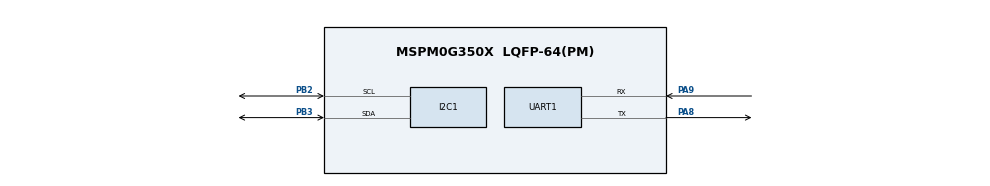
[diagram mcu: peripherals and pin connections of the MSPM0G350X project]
/**
 * @cliArgs --device "MSPM0G350X" --part "Default" --package "LQFP-64(PM)" --product "mspm0_sdk@2.09.00.02"
 * @versions {"tool":"1.25.0+4268"}
 */

/**
 * Import the modules used in this configuration.
 */
const I2C           = scripting.addModule("/ti/driverlib/I2C", {}, false);
const I2C1          = I2C.addInstance();
const PWM           = scripting.addModule("/ti/driverlib/PWM", {}, false);
const PWM1          = PWM.addInstance();
const PWM2          = PWM.addInstance();
const QEI           = scripting.addModule("/ti/driverlib/QEI", {}, false);
const QEI1          = QEI.addInstance();
const SYSCTL        = scripting.addModule("/ti/driverlib/SYSCTL");
const TIMER         = scripting.addModule("/ti/driverlib/TIMER", {}, false);
const TIMER1        = TIMER.addInstance();
const UART          = scripting.addModule("/ti/driverlib/UART", {}, false);
const UART1         = UART.addInstance();
const ProjectConfig = scripting.addModule("/ti/project_config/ProjectConfig");

/**
 * Write custom configuration values to the imported modules.
 */
const gate7  = system.clockTree["MFCLKGATE"];
gate7.enable = true;

I2C1.$name                             = "COMM_I2C";
I2C1.peripheral.sdaPin.$assign         = "PB3";
I2C1.peripheral.sclPin.$assign         = "PB2";
I2C1.sdaPinConfig.$name                = "ti_driverlib_gpio_GPIOPinGeneric0";
I2C1.sdaPinConfig.hideOutputInversion  = scripting.forceWrite(false);
I2C1.sdaPinConfig.onlyInternalResistor = scripting.forceWrite(false);
I2C1.sdaPinConfig.passedPeripheralType = scripting.forceWrite("Digital");
I2C1.sclPinConfig.$name                = "ti_driverlib_gpio_GPIOPinGeneric1";
I2C1.sclPinConfig.hideOutputInversion  = scripting.forceWrite(false);
I2C1.sclPinConfig.onlyInternalResistor = scripting.forceWrite(false);
I2C1.sclPinConfig.passedPeripheralType = scripting.forceWrite("Digital");

const Board = scripting.addModule("/ti/driverlib/Board", {}, false);

PWM1.$name                              = "LEFT_MOTOR";
PWM1.clockDivider                       = 8;
PWM1.clockPrescale                      = 20;
PWM1.timerCount                         = 2000;
PWM1.timerStartTimer                    = true;
PWM1.ccIndex                            = [0];
PWM1.PWM_CHANNEL_0.$name                = "ti_driverlib_pwm_PWMTimerCC0";
PWM1.ccp0PinConfig.direction            = scripting.forceWrite("OUTPUT");
PWM1.ccp0PinConfig.hideOutputInversion  = scripting.forceWrite(false);
PWM1.ccp0PinConfig.onlyInternalResistor = scripting.forceWrite(false);
PWM1.ccp0PinConfig.passedPeripheralType = scripting.forceWrite("Digital");
PWM1.ccp0PinConfig.$name                = "ti_driverlib_gpio_GPIOPinGeneric4";

PWM2.$name                              = "RIGHT_MOTOR";
PWM2.ccIndex                            = [0];
PWM2.clockDivider                       = 8;
PWM2.clockPrescale                      = 20;
PWM2.timerCount                         = 2000;
PWM2.timerStartTimer                    = true;
PWM2.PWM_CHANNEL_0.$name                = "ti_driverlib_pwm_PWMTimerCC2";
PWM2.ccp0PinConfig.direction            = scripting.forceWrite("OUTPUT");
PWM2.ccp0PinConfig.hideOutputInversion  = scripting.forceWrite(false);
PWM2.ccp0PinConfig.onlyInternalResistor = scripting.forceWrite(false);
PWM2.ccp0PinConfig.passedPeripheralType = scripting.forceWrite("Digital");
PWM2.ccp0PinConfig.$name                = "ti_driverlib_gpio_GPIOPinGeneric6";

QEI1.$name               = "QEI_0";
QEI1.clockDivider        = 2;
QEI1.timerStartTimer     = true;
QEI1.ccp0PinConfig.$name = "ti_driverlib_gpio_GPIOPinGeneric5";
QEI1.ccp1PinConfig.$name = "ti_driverlib_gpio_GPIOPinGeneric7";

SYSCTL.clockTreeEn = true;

TIMER1.$name           = "TIMER_0";
TIMER1.timerPeriod     = "5 ms";
TIMER1.timerClkDiv     = 4;
TIMER1.timerStartTimer = true;
TIMER1.interrupts      = ["ZERO"];

UART1.$name                            = "UART_DE";
UART1.uartClkSrc                       = "MFCLK";
UART1.enabledInterrupts                = ["RX"];
UART1.peripheral.rxPin.$assign         = "PA9";
UART1.peripheral.txPin.$assign         = "PA8";
UART1.txPinConfig.direction            = scripting.forceWrite("OUTPUT");
UART1.txPinConfig.hideOutputInversion  = scripting.forceWrite(false);
UART1.txPinConfig.onlyInternalResistor = scripting.forceWrite(false);
UART1.txPinConfig.passedPeripheralType = scripting.forceWrite("Digital");
UART1.txPinConfig.$name                = "ti_driverlib_gpio_GPIOPinGeneric2";
UART1.rxPinConfig.hideOutputInversion  = scripting.forceWrite(false);
UART1.rxPinConfig.onlyInternalResistor = scripting.forceWrite(false);
UART1.rxPinConfig.passedPeripheralType = scripting.forceWrite("Digital");
UART1.rxPinConfig.$name                = "ti_driverlib_gpio_GPIOPinGeneric3";

ProjectConfig.genLibCMSIS = true;

/**
 * Pinmux solution for unlocked pins/peripherals. This ensures that minor changes to the automatic solver in a future
 * version of the tool will not impact the pinmux you originally saw.  These lines can be completely deleted in order to
 * re-solve from scratch.
 */
I2C1.peripheral.$suggestSolution           = "I2C1";
Board.peripheral.$suggestSolution          = "DEBUGSS";
Board.peripheral.swclkPin.$suggestSolution = "PA20";
Board.peripheral.swdioPin.$suggestSolution = "PA19";
PWM1.peripheral.$suggestSolution           = "TIMG0";
PWM1.peripheral.ccp0Pin.$suggestSolution   = "PA12";
PWM2.peripheral.$suggestSolution           = "TIMA1";
PWM2.peripheral.ccp0Pin.$suggestSolution   = "PA10";
QEI1.peripheral.$suggestSolution           = "TIMG8";
QEI1.peripheral.ccp0Pin.$suggestSolution   = "PA1";
QEI1.peripheral.ccp1Pin.$suggestSolution   = "PA0";
TIMER1.peripheral.$suggestSolution         = "TIMA0";
UART1.peripheral.$suggestSolution          = "UART1";
